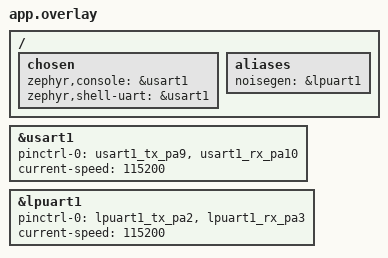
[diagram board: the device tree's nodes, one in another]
/ {
	chosen {
		zephyr,console = &usart1;
		zephyr,shell-uart = &usart1;
	};

	aliases {
		noisegen = &lpuart1;
	};
};

&usart1 {
	pinctrl-0 = <&usart1_tx_pa9 &usart1_rx_pa10>;
	pinctrl-names = "default";
	status = "okay";
	current-speed = <115200>;
};

&lpuart1 {
	pinctrl-0 = <&lpuart1_tx_pa2 &lpuart1_rx_pa3>;
	pinctrl-names = "default";
	status = "okay";
	current-speed = <115200>;
};
